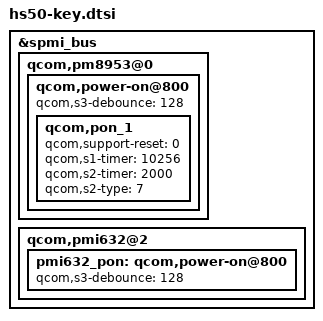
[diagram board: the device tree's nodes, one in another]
&spmi_bus {
	qcom,pm8953@0{
		qcom,power-on@800 {
			qcom,s3-debounce = <128>;
			qcom,pon_1 {
				qcom,support-reset = <0>;
				qcom,s1-timer = <10256>;
				qcom,s2-timer = <2000>;
				qcom,s2-type = <7>;
			};
		};
	};
	qcom,pmi632@2 {
		pmi632_pon: qcom,power-on@800 {
			qcom,s3-debounce = <128>;
		};
	};
};
